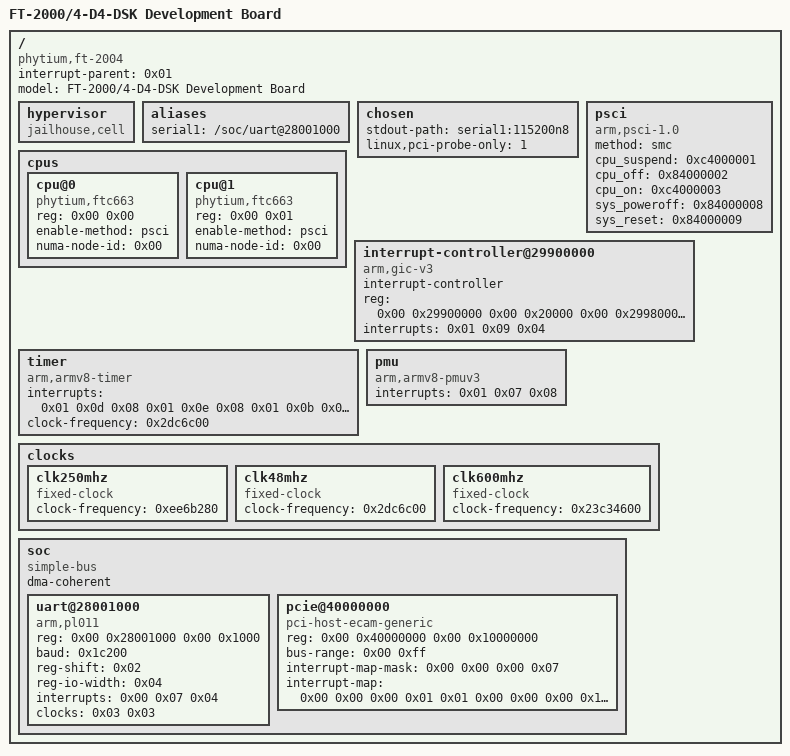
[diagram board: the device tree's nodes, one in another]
/*
 * Jailhouse, a Linux-based partitioning hypervisor
 *
 * Configuration for phytium ft2004 chip linux demo,
 *
 * corresponding to configs/arm64/ft2004-linux-demo.c based on "FT-2000/4-Demo-v1.0-16" board.
 *
 * Copyright (c) Phytium Technology Co., Ltd.
 *
 * Authors:
 *  Shaojun Yang <yangshaojun@phytium.com.cn>
 *
 * This work is licensed under the terms of the GNU GPL, version 2.
 * See the COPYING file in the top-level directory.
 */

/dts-v1/;

/memreserve/	0x0000000080000000 0x0000000000010000;
/ {
	compatible = "phytium,ft-2004";
	interrupt-parent = <0x01>;
	#address-cells = <0x02>;
	#size-cells = <0x02>;
	model = "FT-2000/4-D4-DSK Development Board";

	hypervisor {
		compatible = "jailhouse,cell";
	};

	aliases {
		serial1 = "/soc/uart@28001000";
	};

	chosen {
		stdout-path = "serial1:115200n8";
		linux,pci-probe-only = <1>;
	};

	psci {
		compatible = "arm,psci-1.0";
		method = "smc";
		cpu_suspend = <0xc4000001>;
		cpu_off = <0x84000002>;
		cpu_on = <0xc4000003>;
		sys_poweroff = <0x84000008>;
		sys_reset = <0x84000009>;
	};

	cpus {
		#address-cells = <0x02>;
		#size-cells = <0x00>;

		cpu@0 {
			device_type = "cpu";
			compatible = "phytium,ftc663\0arm,armv8";
			reg = <0x00 0x00>;
			enable-method = "psci";
			numa-node-id = <0x00>;
		};

		cpu@1 {
			device_type = "cpu";
			compatible = "phytium,ftc663\0arm,armv8";
			reg = <0x00 0x01>;
			enable-method = "psci";
			numa-node-id = <0x00>;
		};
	};

	interrupt-controller@29900000 {
		compatible = "arm,gic-v3";
		#interrupt-cells = <0x03>;
		#address-cells = <0x02>;
		#size-cells = <0x02>;
		ranges;
		interrupt-controller;
		reg = <0x00 0x29900000 0x00 0x20000 0x00 0x29980000 0x00 0x80000 0x00 0x29c00000 0x00 0x10000 0x00 0x29c10000 0x00 0x10000 0x00 0x29c20000 0x00 0x10000>;
		interrupts = <0x01 0x09 0x04>;
		phandle = <0x01>;

		/*
		gic-its@29920000 {
			compatible = "arm,gic-v3-its";
			msi-controller;
			reg = <0x00 0x29920000 0x00 0x20000>;
			phandle = <0x05>;
		};
		*/
	};

	timer {
		compatible = "arm,armv8-timer";
		interrupts = <0x01 0x0d 0x08 0x01 0x0e 0x08 0x01 0x0b 0x08 0x01 0x0a 0x08>;
		clock-frequency = <0x2dc6c00>;
	};

	pmu {
		compatible = "arm,armv8-pmuv3";
		interrupts = <0x01 0x07 0x08>;
	};

	clocks {
		#address-cells = <0x02>;
		#size-cells = <0x02>;
		ranges;

		clk250mhz {
			compatible = "fixed-clock";
			#clock-cells = <0x00>;
			clock-frequency = <0xee6b280>;
			phandle = <0x06>;
		};

		clk48mhz {
			compatible = "fixed-clock";
			#clock-cells = <0x00>;
			clock-frequency = <0x2dc6c00>;
			phandle = <0x03>;
		};

		clk600mhz {
			compatible = "fixed-clock";
			#clock-cells = <0x00>;
			clock-frequency = <0x23c34600>;
			phandle = <0x04>;
		};
	};

	soc {
		compatible = "simple-bus";
		#address-cells = <0x02>;
		#size-cells = <0x02>;
		dma-coherent;
		ranges;

		uart@28001000 {
			compatible = "arm,pl011\0arm,primecell";
			reg = <0x00 0x28001000 0x00 0x1000>;
			baud = <0x1c200>;
			reg-shift = <0x02>;
			reg-io-width = <0x04>;
			interrupts = <0x00 0x07 0x04>;
			clocks = <0x03 0x03>;
			clock-names = "uartclk\0apb_pclk";
			status = "okay";
		};

		pcie@40000000 {
			compatible = "pci-host-ecam-generic";
			device_type = "pci";
			#address-cells = <0x03>;
			#size-cells = <0x02>;
			#interrupt-cells = <0x01>;
			reg = <0x00 0x40000000 0x00 0x10000000>;
			//msi-parent = <0x05>;
			bus-range = <0x00 0xff>;
			interrupt-map-mask = <0x00 0x00 0x00 0x07>;
			interrupt-map = <0x00 0x00 0x00 0x01 0x01 0x00 0x00 0x00 0x1c 0x04
							 0x00 0x00 0x00 0x02 0x01 0x00 0x00 0x00 0x1d 0x04
							 0x00 0x00 0x00 0x03 0x01 0x00 0x00 0x00 0x1e 0x04
							 0x00 0x00 0x00 0x04 0x01 0x00 0x00 0x00 0x1f 0x04>;
			ranges = <0x1000000 0x00 0x00 0x00 0x50000000 0x00 0xf00000 0x2000000 0x00 0x58000000 0x00 0x58000000 0x00 0x28000000 0x3000000 0x10 0x00 0x10 0x00 0x10 0x00>;
			status = "okay";
		};
	};
};
